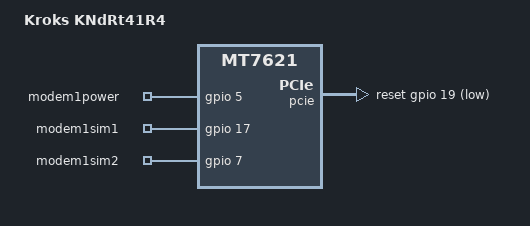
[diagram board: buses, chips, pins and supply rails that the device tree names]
#include "mt7621_kroks_wifi_mt7603_mt7613.dtsi"

/ {
	compatible = "kroks,kndrt41r4", "mediatek,mt7621-soc";
	model = "Kroks KNdRt41R4";

	gpio_export {
		compatible = "gpio-export";
		#size-cells = <0>;

		modem1power {
			gpio-export,name = "modem1power";
			gpio-export,output = <1>;
			gpios = <&gpio 5 GPIO_ACTIVE_HIGH>;
		};

		modem1sim1 {
			gpio-export,name = "modem1sim1";
			gpio-export,output = <1>;
			gpios = <&gpio 17 GPIO_ACTIVE_HIGH>;
		};

		modem1sim2 {
			gpio-export,name = "modem1sim2";
			gpio-export,output = <0>;
			gpios = <&gpio 7 GPIO_ACTIVE_HIGH>;
		};
	};
};

&switch0 {
	ports {
		port@3 {
			status = "okay";
			label = "lan2";
		};

		port@4 {
			status = "okay";
			label = "lan1";
		};
	};
};

&xhci {
	mediatek,u2p-dis-msk = <0x2>;
};

&pcie {
	reset-gpios = <&gpio 19 GPIO_ACTIVE_LOW>,
		      <>,
		      <&gpio 0 GPIO_ACTIVE_LOW>;
};

&pcie2 {
	status = "disabled";
};

&pcie2_phy {
	status = "disabled";
};
